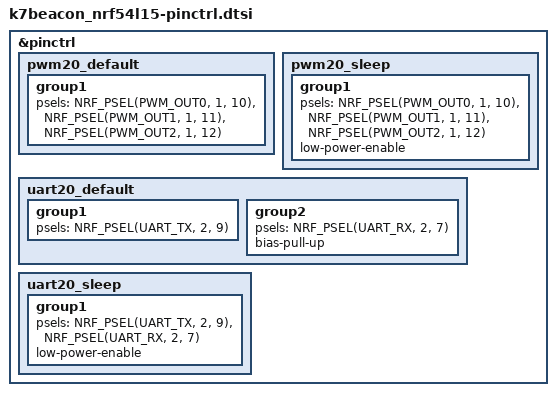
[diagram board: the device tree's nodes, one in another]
/*
 * Copyright (c) 2026
 * SPDX-License-Identifier: Apache-2.0
 *
 * K7 Beacon pin control.
 *
 * RGB LED (common anode -> VDDS, so driven active-low via inverted PWM):
 *   Green = P1.10  (PWM20 OUT0)
 *   Red   = P1.11  (PWM20 OUT1)
 *   Blue  = P1.12  (PWM20 OUT2)
 * All three are P1 (LP-domain) pins, reachable by PWM20.
 *
 * UART20 (optional debug, RXD/TXD on the test points):
 *   TXD = P2.09, RXD = P2.07
 */

&pinctrl {
	/omit-if-no-ref/ pwm20_default: pwm20_default {
		group1 {
			psels = <NRF_PSEL(PWM_OUT0, 1, 10)>,
				<NRF_PSEL(PWM_OUT1, 1, 11)>,
				<NRF_PSEL(PWM_OUT2, 1, 12)>;
		};
	};

	/omit-if-no-ref/ pwm20_sleep: pwm20_sleep {
		group1 {
			psels = <NRF_PSEL(PWM_OUT0, 1, 10)>,
				<NRF_PSEL(PWM_OUT1, 1, 11)>,
				<NRF_PSEL(PWM_OUT2, 1, 12)>;
			low-power-enable;
		};
	};

	/omit-if-no-ref/ uart20_default: uart20_default {
		group1 {
			psels = <NRF_PSEL(UART_TX, 2, 9)>;
		};
		group2 {
			psels = <NRF_PSEL(UART_RX, 2, 7)>;
			bias-pull-up;
		};
	};

	/omit-if-no-ref/ uart20_sleep: uart20_sleep {
		group1 {
			psels = <NRF_PSEL(UART_TX, 2, 9)>,
				<NRF_PSEL(UART_RX, 2, 7)>;
			low-power-enable;
		};
	};
};
